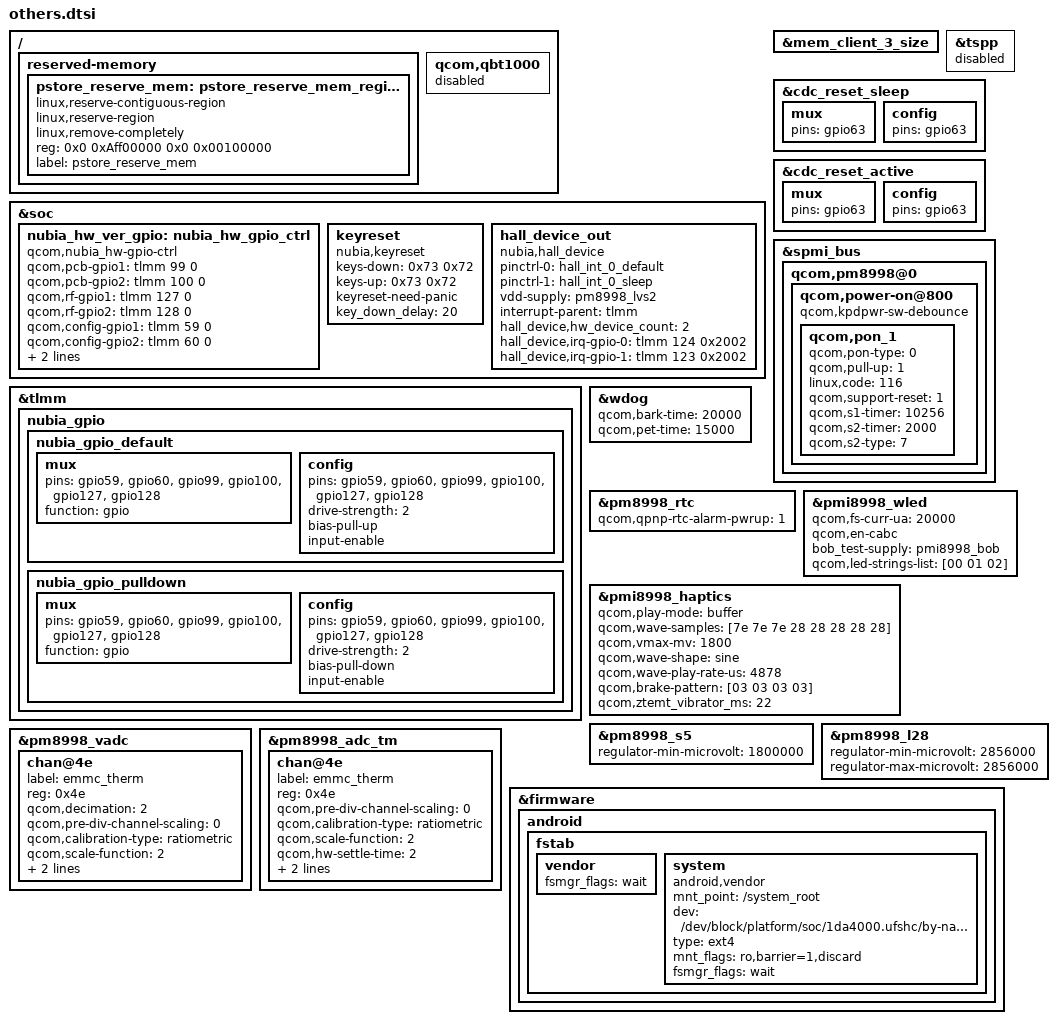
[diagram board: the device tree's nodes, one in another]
&soc {
	/delete-node/ gpio-regulator@0;
	/delete-node/ cam_focus;

	//nubia add hw version
	nubia_hw_ver_gpio: nubia_hw_gpio_ctrl {
		compatible = "qcom,nubia_hw-gpio-ctrl";
		qcom,pcb-gpio1 = <&tlmm 99 0>;
		qcom,pcb-gpio2 = <&tlmm 100 0>;
		qcom,rf-gpio1 = <&tlmm  127 0>;
		qcom,rf-gpio2 = <&tlmm 128 0>;
		qcom,config-gpio1 = <&tlmm 59 0>;
		qcom,config-gpio2 = <&tlmm 60 0>;
		//qcom,pm-gpio1 = <&pm8998_gpios 12 0>;
		//qcom,pm-gpio2 = <&pm8998_gpios 12 0>;
		//qcom,pcb-pm-adc_channel = <0x38>;
		//qcom,config-pm-adc_channel = <0x51>;//powerup 100k
		//qcom,nubia_hw-vadc = <&pm8998_vadc>;
		pinctrl-names = "pull_up_default","pull_down_default";
		pinctrl-0 = <&nubia_gpio_default>;
		pinctrl-1 = <&nubia_gpio_pulldown>;
	};

	keyreset {
		compatible = "nubia,keyreset";
		keys-down = <0x73 0x72>;
		keys-up = <0x73 0x72>;
		keyreset-need-panic;
		key_down_delay = <20>;
	};
	
	//Nubia add vibrator start
	hall_device_out {
		compatible = "nubia,hall_device";
		status = "okay";
		pinctrl-names = "hall_default","hall_sleep";
		pinctrl-0 = <&hall_int_0_default >;
		pinctrl-1 = <&hall_int_0_sleep >;
		vdd-supply = <&pm8998_lvs2>;
		interrupt-parent = <&tlmm>;
		hall_device,hw_device_count = <2>;
		hall_device,irq-gpio-0 = <&tlmm 124 0x2002>;
		hall_device,irq-gpio-1 = <&tlmm 123 0x2002>;
	};
	//Nubia add vibrator end
};

&mem_client_3_size {
	/delete-property/ qcom,allocate-boot-time;
};

/* pstore mem*/
/ {
	reserved-memory {
		pstore_reserve_mem: pstore_reserve_mem_region@Aff00000 {
			linux,reserve-contiguous-region;
			linux,reserve-region;
			linux,remove-completely;
			reg = <0x0 0xAff00000 0x0 0x00100000>;
			label = "pstore_reserve_mem";
		};
	};

	qcom,qbt1000 {
		status = "disabled";
	};
};

&tspp {
	status = "disabled";
};

&tlmm {
	nubia_gpio {
		nubia_gpio_default: nubia_gpio_default{
			mux {
				pins = "gpio59", "gpio60", "gpio99", "gpio100", "gpio127", "gpio128";
				function = "gpio";
			};

			config {
				pins = "gpio59", "gpio60", "gpio99", "gpio100", "gpio127", "gpio128";
				drive-strength = <2>; /* 2 mA */
				bias-pull-up; /* pull up */
				input-enable;
			};
		};
		nubia_gpio_pulldown: nubia_gpio_pulldown{
			mux {
				pins = "gpio59", "gpio60", "gpio99", "gpio100", "gpio127", "gpio128";
				function = "gpio";
			};

			config {
				pins = "gpio59", "gpio60", "gpio99", "gpio100", "gpio127", "gpio128";
				drive-strength = <2>; /* 2 mA */
				bias-pull-down; /* pull down */
				input-enable;
			};
		};
	};
};


&cdc_reset_sleep {
	mux {
		pins = "gpio63";
	};
	config {
		pins = "gpio63";
	};
};

&cdc_reset_active {
	mux {
		pins = "gpio63";
	};
	config {
		pins = "gpio63";
	};
};

&spmi_bus {
	qcom,pm8998@0 {
		qcom,power-on@800 {
			qcom,kpdpwr-sw-debounce;
			
			qcom,pon_1 {
				qcom,pon-type = <0>;
				qcom,pull-up = <1>;
				linux,code = <116>;
				qcom,support-reset = <1>;
				qcom,s1-timer = <10256>;
				qcom,s2-timer = <2000>;
				qcom,s2-type = <7>;
			};
		};
	};
};	

&wdog {
        qcom,bark-time = <20000>;
        qcom,pet-time = <15000>;
};

&pm8998_rtc {
	qcom,qpnp-rtc-alarm-pwrup = <1>;
};

&pmi8998_wled {
	/delete-property/ qcom,auto-calibration-enable;

	qcom,fs-curr-ua = <20000>;
	qcom,en-cabc;
	bob_test-supply = <&pmi8998_bob>;
	qcom,led-strings-list = [00 01 02];
};

&pmi8998_haptics {
	qcom,play-mode = "buffer";
	qcom,wave-samples = [7e 7e 7e 28 28 28 28 28];
	qcom,vmax-mv = <1800>;
	qcom,wave-shape = "sine";
	qcom,wave-play-rate-us = <4878>;
	qcom,brake-pattern = [03 03 03 03];
	qcom,ztemt_vibrator_ms =<22>;
};

&pm8998_s5 {
	regulator-min-microvolt = <1800000>;
};

&pm8998_l28 {
	regulator-min-microvolt = <2856000>;
	regulator-max-microvolt = <2856000>;
};

&pm8998_vadc {
	chan@4e {
		label = "emmc_therm";
		reg = <0x4e>;
		qcom,decimation = <2>;
		qcom,pre-div-channel-scaling = <0>;
		qcom,calibration-type = "ratiometric";
		qcom,scale-function = <2>;
		qcom,hw-settle-time = <2>;
		qcom,fast-avg-setup = <0>;
	};
};

&pm8998_adc_tm {
	chan@4e {
		label = "emmc_therm";
		reg = <0x4e>;
		qcom,pre-div-channel-scaling = <0>;
		qcom,calibration-type = "ratiometric";
		qcom,scale-function = <2>;
		qcom,hw-settle-time = <2>;
		qcom,btm-channel-number = <0x80>;
		qcom,thermal-node;
	};
};

&firmware{
	android{
		fstab{
			vendor {
				fsmgr_flags = "wait";
				status = "ok";
			};
			
			system {
				mnt_point = "/system_root";
				compatible = "android,vendor";
				dev = "/dev/block/platform/soc/1da4000.ufshc/by-name/system";
				type = "ext4";
				mnt_flags = "ro,barrier=1,discard";
				fsmgr_flags = "wait";
				status = "ok";
			};
		};
	};
};
